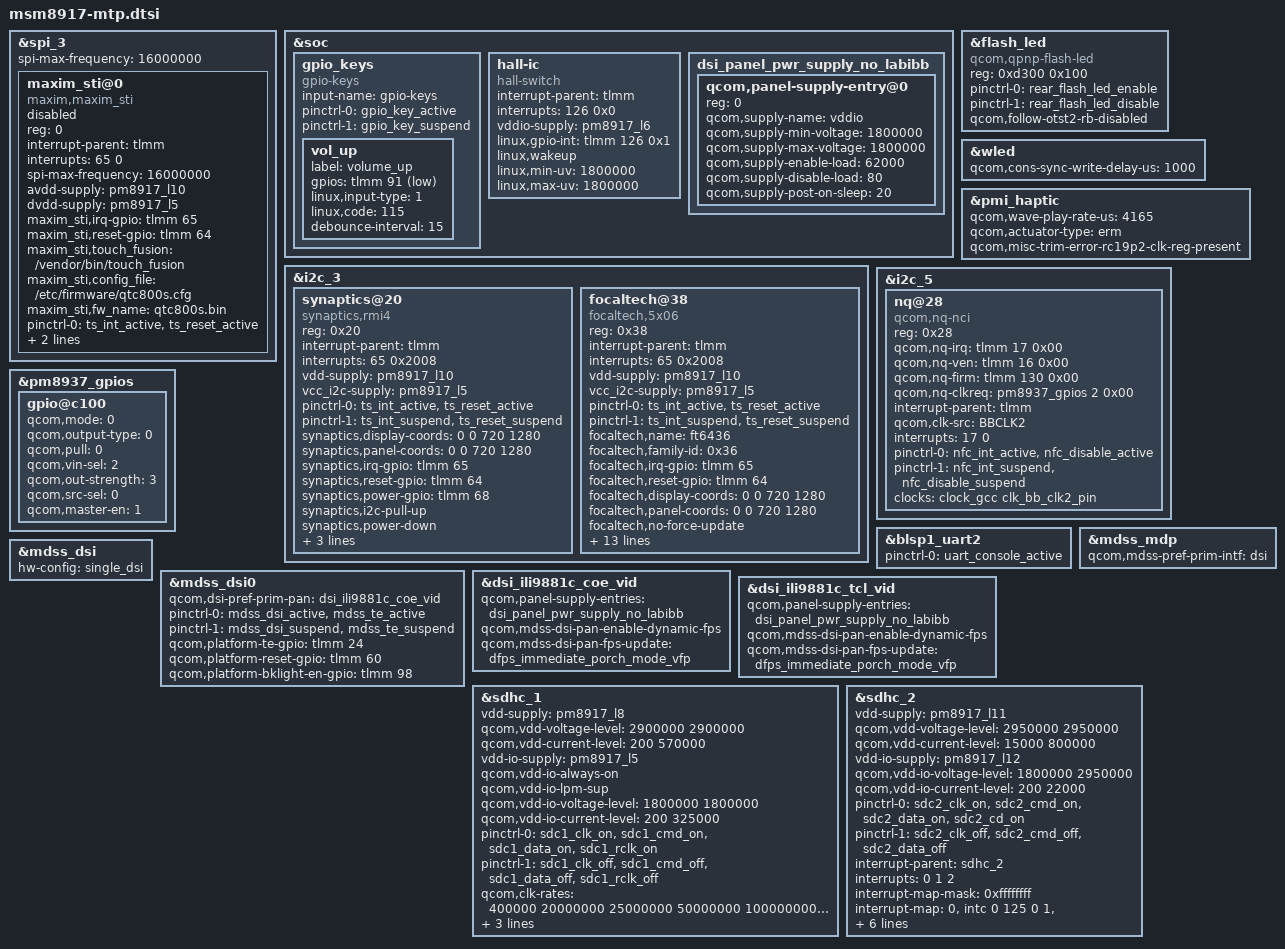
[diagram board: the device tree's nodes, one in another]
/*
 * Copyright (c) 2015-2016, The Linux Foundation. All rights reserved.
 *
 * This program is free software; you can redistribute it and/or modify
 * it under the terms of the GNU General Public License version 2 and
 * only version 2 as published by the Free Software Foundation.
 *
 * This program is distributed in the hope that it will be useful,
 * but WITHOUT ANY WARRANTY; without even the implied warranty of
 * MERCHANTABILITY or FITNESS FOR A PARTICULAR PURPOSE.  See the
 * GNU General Public License for more details.
 */

#include "msm8917-pinctrl.dtsi"
#include "msm8917-camera-sensor-mtp.dtsi"

&spi_3 { /* BLSP1 QUP3 */
	spi-max-frequency = <16000000>;
	maxim_sti@0 {
		status = "disabled";
		compatible = "maxim,maxim_sti";
		reg = <0>;
		interrupt-parent = <&tlmm>;
		interrupts = <65 0>;
		spi-max-frequency = <16000000>;
		avdd-supply = <&pm8917_l10>;
		dvdd-supply = <&pm8917_l5>;
		maxim_sti,irq-gpio = <&tlmm 65 0x00>;
		maxim_sti,reset-gpio = <&tlmm 64 0x00>;
		maxim_sti,touch_fusion = "/vendor/bin/touch_fusion";
		maxim_sti,config_file = "/etc/firmware/qtc800s.cfg";
		maxim_sti,fw_name = "qtc800s.bin";
		pinctrl-names = "pmx_ts_active","pmx_ts_suspend",
			"pmx_ts_release";
		pinctrl-0 = <&ts_int_active &ts_reset_active>;
		pinctrl-1 = <&ts_int_suspend &ts_reset_suspend>;
		pinctrl-2 = <&ts_release>;
	};
};

&soc {
	gpio_keys {
		compatible = "gpio-keys";
		input-name = "gpio-keys";
		pinctrl-names = "tlmm_gpio_key_active","tlmm_gpio_key_suspend";
		pinctrl-0 = <&gpio_key_active>;
		pinctrl-1 = <&gpio_key_suspend>;

		vol_up {
			label = "volume_up";
			gpios = <&tlmm 91 0x1>;
			linux,input-type = <1>;
			linux,code = <115>;
			debounce-interval = <15>;
		};
	};

	//wangyanhui add hall ic
	hall-ic{//yangliang add for hall sensor;20150902
		compatible = "hall-switch";
		//pinctrl-names = "default";
		//pinctrl-0 = <&hall_sensor_int_default>;
		interrupt-parent = <&tlmm>;
		interrupts = <126 0x0>;
		vddio-supply = <&pm8917_l6>;
		linux,gpio-int = <&tlmm 126 0x1>;
		linux,wakeup;
		linux,min-uv = <1800000>;
		linux,max-uv = <1800000>;
	};
   dsi_panel_pwr_supply_no_labibb:dsi_panel_pwr_supply_no_labibb {
	#address-cells = <1>;
	#size-cells = <0>;
	qcom,panel-supply-entry@0 {
	reg = <0>;
	qcom,supply-name = "vddio";
	qcom,supply-min-voltage = <1800000>;
	qcom,supply-max-voltage = <1800000>;
	qcom,supply-enable-load = <62000>;
	qcom,supply-disable-load = <80>;
	qcom,supply-post-on-sleep = <20>;
	};
};
};

&flash_led {
	compatible = "qcom,qpnp-flash-led";
	reg = <0xd300 0x100>;
	pinctrl-names = "flash_led_enable","flash_led_disable";
	pinctrl-0 = <&rear_flash_led_enable>;
	pinctrl-1 = <&rear_flash_led_disable>;
	qcom,follow-otst2-rb-disabled;
};

&wled {
	qcom,cons-sync-write-delay-us = <1000>;
};

&pmi_haptic{
	qcom,wave-play-rate-us = <4165>;
	qcom,actuator-type = "erm"; //vib use erm mode  
	/*qcom,actuator-type = "lra";
	qcom,lra-auto-res-mode="qwd";
	qcom,lra-high-z="opt1";
	qcom,lra-res-cal-period = <4>;
	qcom,correct-lra-drive-freq;*/
	qcom,misc-trim-error-rc19p2-clk-reg-present;
};

// add i2c3 for touchpanel
&i2c_3{
		
		synaptics@20 {
				compatible = "synaptics,rmi4";
				reg = <0x20>;
				interrupt-parent = <&tlmm>;
				interrupts = <65 0x2008>;
		                vdd-supply = <&pm8917_l10>;
		                vcc_i2c-supply = <&pm8917_l5>;
				// pins used by touchscreen 
				pinctrl-names = "pmx_ts_active","pmx_ts_suspend";
				pinctrl-0 = <&ts_int_active &ts_reset_active>;
				pinctrl-1 = <&ts_int_suspend &ts_reset_suspend>;
				synaptics,display-coords = <0 0 720 1280>;
				synaptics,panel-coords = <0 0 720 1280>;
				synaptics,irq-gpio = <&tlmm 65 0x2008>;
				synaptics,reset-gpio = <&tlmm 64 0x0>;
				synaptics,power-gpio = <&tlmm 68 0x0>;
				synaptics,i2c-pull-up;
				synaptics,power-down;
				synaptics,disable-gpios;
		                synaptics,power-delay-ms = <160>;
		                synaptics,reset-delay-ms = <100>;
				//synaptics,fw-image-name = "YEJI_PR1723210-S3202_TINNO_P7021.img";
				//synaptics,fw-image-name-ttouch = "";
			};

		focaltech@38 {
			compatible = "focaltech,5x06";
			reg = <0x38>;
			interrupt-parent = <&tlmm>;
			interrupts = <65 0x2008>;
			vdd-supply = <&pm8917_l10>;
			vcc_i2c-supply = <&pm8917_l5>;
			/* pins used by touchscreen */
			pinctrl-names = "pmx_ts_active","pmx_ts_suspend";//,"pmx_ts_release";
			pinctrl-0 = <&ts_int_active &ts_reset_active>;
			pinctrl-1 = <&ts_int_suspend &ts_reset_suspend>;
			//pinctrl-2 = <&ts_release>;
			focaltech,name = "ft6436";
			focaltech,family-id = <0x36>;
			focaltech,irq-gpio = <&tlmm 65 0x0>;
			focaltech,reset-gpio = <&tlmm 64 0x0>;
			focaltech,display-coords = <0 0 720 1280>;
			focaltech,panel-coords = <0 0 720 1280>;
			focaltech,no-force-update;
			focaltech,i2c-pull-up;
			focaltech,group-id = <1>;
			focaltech,hard-reset-delay-ms = <20>;
			focaltech,soft-reset-delay-ms = <200>;
			focaltech,num-max-touches = <5>;
			focaltech,fw-delay-aa-ms = <30>;
			focaltech,fw-delay-55-ms = <30>;
			focaltech,fw-upgrade-id1 = <0x79>;
			focaltech,fw-upgrade-id2 = <0x18>;
			focaltech,fw-delay-readid-ms = <10>;
			focaltech,fw-delay-era-flsh-ms = <2000>;
			focaltech,fw-auto-cal;
			focaltech,ignore-id-check;
		};
}; 

//yixuhong 20170329 add for nfc
&i2c_5 { /* BLSP2 QUP1 (NFC) */
	nq@28 {
		compatible = "qcom,nq-nci";
		reg = <0x28>;
		qcom,nq-irq = <&tlmm 17 0x00>;
		qcom,nq-ven = <&tlmm 16 0x00>;
		qcom,nq-firm = <&tlmm 130 0x00>;
		qcom,nq-clkreq = <&pm8937_gpios 2 0x00>;
		interrupt-parent = <&tlmm>;
		qcom,clk-src = "BBCLK2";
		interrupts = <17 0>;
		interrupt-names = "nfc_irq";
		pinctrl-names = "nfc_active", "nfc_suspend";
		pinctrl-0 = <&nfc_int_active &nfc_disable_active>;
		pinctrl-1 = <&nfc_int_suspend &nfc_disable_suspend>;
		clocks = <&clock_gcc clk_bb_clk2_pin>;
		clock-names = "ref_clk";
	};
};

&pm8937_gpios {
	/* GPIO 2 (NFC_CLK_REQ) */
	gpio@c100 {
		qcom,mode = <0>;
		qcom,output-type = <0>;
		qcom,pull = <0>;
		qcom,vin-sel = <2>;
		qcom,out-strength = <3>;
		qcom,src-sel = <0>;
		qcom,master-en = <1>;
		status = "okay";
	};
};

&blsp1_uart2 {
	status = "ok";
	pinctrl-names = "default";
	pinctrl-0 = <&uart_console_active>;
};

#include "msm8937-mdss-panels.dtsi"

&mdss_mdp {
	qcom,mdss-pref-prim-intf = "dsi";
};

&mdss_dsi {
	hw-config = "single_dsi";
};
/*
&mdss_dsi0 {
	qcom,dsi-pref-prim-pan = <&dsi_truly_720_vid>;
	pinctrl-names = "mdss_default", "mdss_sleep";
	pinctrl-0 = <&mdss_dsi_active &mdss_te_active>;
	pinctrl-1 = <&mdss_dsi_suspend &mdss_te_suspend>;

	qcom,platform-te-gpio = <&tlmm 24 0>;
	qcom,platform-reset-gpio = <&tlmm 60 0>;
	qcom,platform-bklight-en-gpio = <&tlmm 98 0>;
};

&dsi_truly_720_vid {
	qcom,panel-supply-entries = <&dsi_panel_pwr_supply>;
	qcom,mdss-dsi-pan-enable-dynamic-fps;
	qcom,mdss-dsi-pan-fps-update = "dfps_immediate_porch_mode_vfp";
};

&dsi_truly_720_cmd {
	qcom,panel-supply-entries = <&dsi_panel_pwr_supply>;
	qcom,ulps-enabled;
	qcom,partial-update-enabled;
	qcom,panel-roi-alignment = <2 2 2 2 2 2>;
};*/


&mdss_dsi0 {
	qcom,dsi-pref-prim-pan = <&dsi_ili9881c_coe_vid>;
	pinctrl-names = "mdss_default", "mdss_sleep";
	pinctrl-0 = <&mdss_dsi_active &mdss_te_active>;
	pinctrl-1 = <&mdss_dsi_suspend &mdss_te_suspend>;

	qcom,platform-te-gpio = <&tlmm 24 0>;
	qcom,platform-reset-gpio = <&tlmm 60 0>;
	qcom,platform-bklight-en-gpio = <&tlmm 98 0>;
};



&dsi_ili9881c_coe_vid {
	qcom,panel-supply-entries = <&dsi_panel_pwr_supply_no_labibb>;
	qcom,mdss-dsi-pan-enable-dynamic-fps;
	qcom,mdss-dsi-pan-fps-update = "dfps_immediate_porch_mode_vfp";
};

&dsi_ili9881c_tcl_vid {
	qcom,panel-supply-entries = <&dsi_panel_pwr_supply_no_labibb>;
	qcom,mdss-dsi-pan-enable-dynamic-fps;
	qcom,mdss-dsi-pan-fps-update = "dfps_immediate_porch_mode_vfp";
};

&sdhc_1 {
	/* device core power supply */
	vdd-supply = <&pm8917_l8>;
	qcom,vdd-voltage-level = <2900000 2900000>;
	qcom,vdd-current-level = <200 570000>;

	/* device communication power supply */
	vdd-io-supply = <&pm8917_l5>;
	qcom,vdd-io-always-on;
	qcom,vdd-io-lpm-sup;
	qcom,vdd-io-voltage-level = <1800000 1800000>;
	qcom,vdd-io-current-level = <200 325000>;

	pinctrl-names = "active", "sleep";
	pinctrl-0 = <&sdc1_clk_on &sdc1_cmd_on &sdc1_data_on &sdc1_rclk_on>;
	pinctrl-1 = <&sdc1_clk_off &sdc1_cmd_off &sdc1_data_off &sdc1_rclk_off>;

	qcom,clk-rates = <400000 20000000 25000000 50000000 100000000 192000000
								384000000>;
	qcom,nonremovable;
	qcom,bus-speed-mode = "HS400_1p8v", "HS200_1p8v", "DDR_1p8v";

	status = "ok";
};

&sdhc_2 {
	/* device core power supply */
	vdd-supply = <&pm8917_l11>;
	qcom,vdd-voltage-level = <2950000 2950000>;
	qcom,vdd-current-level = <15000 800000>;

	/* device communication power supply */
	vdd-io-supply = <&pm8917_l12>;
	qcom,vdd-io-voltage-level = <1800000 2950000>;
	qcom,vdd-io-current-level = <200 22000>;

	pinctrl-names = "active", "sleep";
	pinctrl-0 = <&sdc2_clk_on &sdc2_cmd_on &sdc2_data_on &sdc2_cd_on>;
	pinctrl-1 = <&sdc2_clk_off &sdc2_cmd_off &sdc2_data_off>;

	#address-cells = <0>;
	interrupt-parent = <&sdhc_2>;
	interrupts = <0 1 2>;
	#interrupt-cells = <1>;
	interrupt-map-mask = <0xffffffff>;
	interrupt-map = <0 &intc 0 125 0
		1 &intc 0 221 0
		2 &tlmm 67 0>;
	interrupt-names = "hc_irq", "pwr_irq", "status_irq";
	cd-gpios = <&tlmm 67 0x0>;

	qcom,clk-rates = <400000 20000000 25000000 50000000 100000000
								200000000>;
	qcom,bus-speed-mode = "SDR12", "SDR25", "SDR50", "DDR50", "SDR104";

	status = "ok";
};
